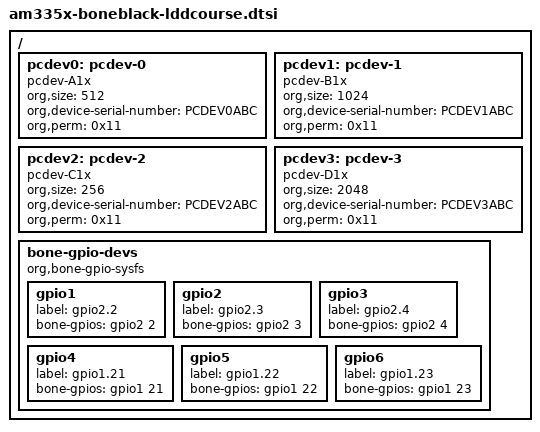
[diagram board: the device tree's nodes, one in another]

/ {
	pcdev0: pcdev-0 {
		compatible = "pcdev-A1x";
		org,size = <512>;
		org,device-serial-number = "PCDEV0ABC";
		org,perm = <0x11>;
	};
	pcdev1: pcdev-1 {
		compatible = "pcdev-B1x";
		org,size = <1024>;
		org,device-serial-number = "PCDEV1ABC";
		org,perm = <0x11>;
	};
	pcdev2: pcdev-2 {
		compatible = "pcdev-C1x";
		org,size = <256>;
		org,device-serial-number = "PCDEV2ABC";
		org,perm = <0x11>;
	};
	pcdev3: pcdev-3 {
		compatible = "pcdev-D1x";
		org,size = <2048>;
		org,device-serial-number = "PCDEV3ABC";
		org,perm = <0x11>;
	};
	bone-gpio-devs {
		compatible = "org,bone-gpio-sysfs";
		gpio1 {
			label = "gpio2.2";
			bone-gpios = <&gpio2 2 GPIO_ACTIVE_HIGH>;
		};
		gpio2 {
                        label = "gpio2.3";
                        bone-gpios = <&gpio2 3 GPIO_ACTIVE_HIGH>;
                };
		gpio3 {
                        label = "gpio2.4";
                        bone-gpios = <&gpio2 4 GPIO_ACTIVE_HIGH>;
                };
		gpio4 {
                        label = "gpio1.21";
                        bone-gpios = <&gpio1 21 GPIO_ACTIVE_HIGH>;
                };
		gpio5 {
                        label = "gpio1.22";
                        bone-gpios = <&gpio1 22 GPIO_ACTIVE_HIGH>;
                };
		gpio6 {
                        label = "gpio1.23";
                        bone-gpios = <&gpio1 23 GPIO_ACTIVE_HIGH>;
                };
	};
};
